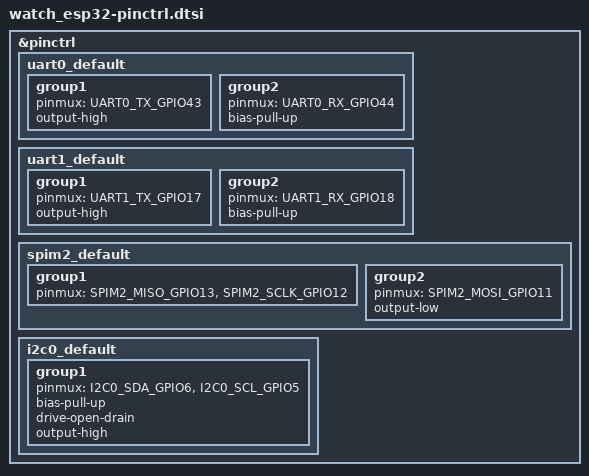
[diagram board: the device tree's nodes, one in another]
#include <zephyr/dt-bindings/pinctrl/esp-pinctrl-common.h>
#include <zephyr/dt-bindings/pinctrl/esp32s3-pinctrl.h>
#include <zephyr/dt-bindings/pinctrl/esp32s3-gpio-sigmap.h>

&pinctrl {
    //Serial Comms
    uart0_default: uart0_default{
        group1 {
            pinmux = <UART0_TX_GPIO43>;
            output-high;
        };
        group2 {
            pinmux = <UART0_RX_GPIO44>;
            bias-pull-up;
        };
    };

    //MAX-M10S
    uart1_default: uart1_default{
        group1 {
            pinmux = <UART1_TX_GPIO17>;
            output-high;
        };
        group2 {
            pinmux = <UART1_RX_GPIO18>;
            bias-pull-up;
        };
    };

    //LSM6DSO, GC9A01
    spim2_default: spim2_default{
        group1 {
            pinmux = <SPIM2_MISO_GPIO13>,
                     <SPIM2_SCLK_GPIO12>;
        };
        group2 {
            pinmux = <SPIM2_MOSI_GPIO11>;
            output-low;
        };
    };

    //BMP388, DRV2605, MAX30105
    i2c0_default: i2c0_default{
        group1 {
            pinmux = <I2C0_SDA_GPIO6>,
                     <I2C0_SCL_GPIO5>;
            bias-pull-up;
            drive-open-drain;
            output-high;
        };
    };
};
